# nrf52840 register map
Vendor: Nordic Semiconductor; Series: nrf52; File version: 1
CPU: CM4 r0p1, little endian, MPU, FPU, 3 interrupt priority bits
Registers are 32-bit, read-write, reset 0x0 unless marked. A register's access mark holds for its fields unless they carry their own. Offsets are from the block's base; [hi:lo] are bit positions; {n}, {i} and the like mark numbered series; <NAME> marks a mode.

## WDT — Watchdog Timer
Base 0x40010000
0x00 TASKS_START wo — Start the watchdog
  [0] TASKS_START
0x100 EVENTS_TIMEOUT — Watchdog timeout
  [0] EVENTS_TIMEOUT
0x304 INTENSET — Enable interrupt
  [0] TIMEOUT — Write '1' to enable interrupt for TIMEOUT event
    on read: 0=Disabled (Read: Disabled); 1=Enabled (Read: Enabled) | on write: 1=Set (Enable)
0x308 INTENCLR — Disable interrupt
  [0] TIMEOUT — Write '1' to disable interrupt for TIMEOUT event
    on read: 0=Disabled (Read: Disabled); 1=Enabled (Read: Enabled) | on write: 1=Clear (Disable)
0x400 RUNSTATUS ro
  [0] RUNSTATUS — Indicates whether or not the watchdog is running
    0=NotRunning (Watchdog not running); 1=Running (Watchdog is running)
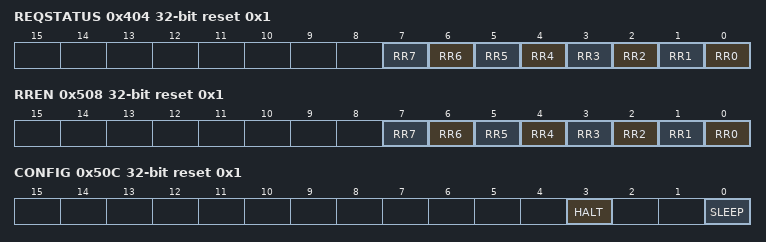
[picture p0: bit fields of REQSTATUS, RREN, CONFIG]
0x404 REQSTATUS ro reset 0x1 — Request status
  [n] RR{n} (n=0..7) — Request status for RR[{n}] register
    0=DisabledOrRequested (RR[{n}] register is not enabled, or are already requesting reload); 1=EnabledAndUnrequested (RR[{n}] register is enabled, and are not yet requesting reload)
0x504 CRV reset 0xFFFFFFFF — Counter reload value
  [31:0] CRV — Counter reload value in number of cycles of the 32.768 kHz clock
0x508 RREN reset 0x1 — Enable register for reload request registers
  [n] RR{n} (n=0..7) — Enable or disable RR[{n}] register
    0=Disabled (Disable RR[{n}] register); 1=Enabled (Enable RR[{n}] register)
0x50C CONFIG reset 0x1 — Configuration register
  [3] HALT — Configure the watchdog to either be paused, or kept running, while the CPU is halted by the debugger
    0=Pause watchdog while the CPU is halted by the debugger; 1=Run (Keep the watchdog running while the CPU is halted by the debugger)
  [0] SLEEP — Configure the watchdog to either be paused, or kept running, while the CPU is sleeping
    0=Pause watchdog while the CPU is sleeping; 1=Run (Keep the watchdog running while the CPU is sleeping)
{0x600+4i} RR[{i}] (i=0..7) wo — Description collection[n]: Reload request n
  [31:0] RR — Reload request register
    0x6E524635=Reload (Value to request a reload of the watchdog timer)

## COMP — Comparator
Base 0x40013000
0x00 TASKS_START wo — Start comparator
  [0] TASKS_START
0x04 TASKS_STOP wo — Stop comparator
  [0] TASKS_STOP
0x08 TASKS_SAMPLE wo — Sample comparator value
  [0] TASKS_SAMPLE
0x100 EVENTS_READY — COMP is ready and output is valid
  [0] EVENTS_READY
0x104 EVENTS_DOWN — Downward crossing
  [0] EVENTS_DOWN
0x108 EVENTS_UP — Upward crossing
  [0] EVENTS_UP
0x10C EVENTS_CROSS — Downward or upward crossing
  [0] EVENTS_CROSS
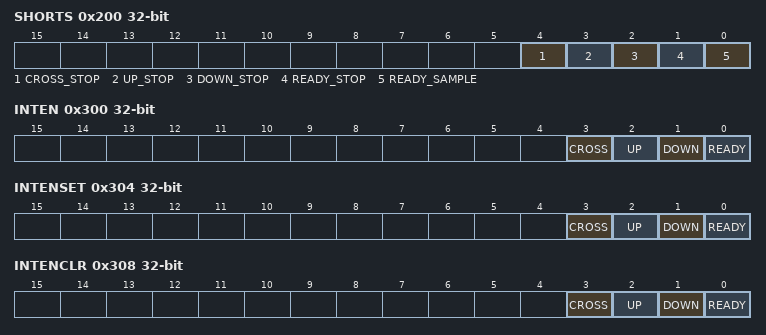
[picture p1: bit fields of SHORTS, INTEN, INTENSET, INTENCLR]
0x200 SHORTS — Shortcut register
  [all] fields
    0=Disabled (Disable shortcut); 1=Enabled (Enable shortcut)
  [4] CROSS_STOP — Shortcut between CROSS event and STOP task
  [3] UP_STOP — Shortcut between UP event and STOP task
  [2] DOWN_STOP — Shortcut between DOWN event and STOP task
  [1] READY_STOP — Shortcut between READY event and STOP task
  [0] READY_SAMPLE — Shortcut between READY event and SAMPLE task
0x300 INTEN — Enable or disable interrupt
  [all] fields
    0=Disabled; 1=Enabled
  [3] CROSS — Enable or disable interrupt for CROSS event
  [2] UP — Enable or disable interrupt for UP event
  [1] DOWN — Enable or disable interrupt for DOWN event
  [0] READY — Enable or disable interrupt for READY event
0x304 INTENSET — Enable interrupt
  [all] fields
    on read: 0=Disabled (Read: Disabled); 1=Enabled (Read: Enabled) | on write: 1=Set (Enable)
  [3] CROSS — Write '1' to enable interrupt for CROSS event
  [2] UP — Write '1' to enable interrupt for UP event
  [1] DOWN — Write '1' to enable interrupt for DOWN event
  [0] READY — Write '1' to enable interrupt for READY event
0x308 INTENCLR — Disable interrupt
  [all] fields
    on read: 0=Disabled (Read: Disabled); 1=Enabled (Read: Enabled) | on write: 1=Clear (Disable)
  [3] CROSS — Write '1' to disable interrupt for CROSS event
  [2] UP — Write '1' to disable interrupt for UP event
  [1] DOWN — Write '1' to disable interrupt for DOWN event
  [0] READY — Write '1' to disable interrupt for READY event
0x400 RESULT ro — Compare result
  [0] RESULT — Result of last compare. Decision point SAMPLE task.
    0=Below (Input voltage is below the threshold (VIN+ < VIN-)); 1=Above (Input voltage is above the threshold (VIN+ > VIN-))
0x500 ENABLE — COMP enable
  [1:0] ENABLE — Enable or disable COMP
    0=Disabled; 2=Enabled
0x504 PSEL — Pin select
  [2:0] PSEL — Analog pin select
    {v}=AnalogInput{v} (AIN{v} selected as analog input) (v=0..7)
0x508 REFSEL reset 0x4 — Reference source select for single-ended mode
  [2:0] REFSEL — Reference select
    0=Int1V2 (VREF = internal 1.2 V reference (VDD >= 1.7 V)); 1=Int1V8 (VREF = internal 1.8 V reference (VDD >= VREF + 0.2 V)); 2=Int2V4 (VREF = internal 2.4 V reference (VDD >= VREF + 0.2 V)); 4=VDD (VREF = VDD); 5=ARef (VREF = AREF (VDD >= VREF >= AREFMIN))
0x50C EXTREFSEL — External reference select
  [2:0] EXTREFSEL — External analog reference select
    {v}=AnalogReference{v} (Use AIN{v} as external analog reference) (v=0..7)
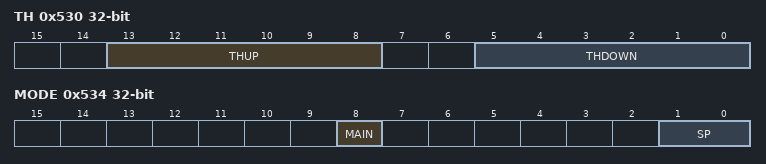
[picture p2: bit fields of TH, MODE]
0x530 TH — Threshold configuration for hysteresis unit
  [13:8] THUP — VUP = (THUP+1)/64*VREF
  [5:0] THDOWN — VDOWN = (THDOWN+1)/64*VREF
0x534 MODE — Mode configuration
  [8] MAIN — Main operation modes
    0=SE (Single-ended mode); 1=Differential mode
  [1:0] SP — Speed and power modes
    0=Low (Low-power mode); 1=Normal mode; 2=High-speed mode
0x538 HYST — Comparator hysteresis enable
  [0] HYST — Comparator hysteresis
    0=NoHyst (Comparator hysteresis disabled); 1=Hyst50mV (Comparator hysteresis enabled)
